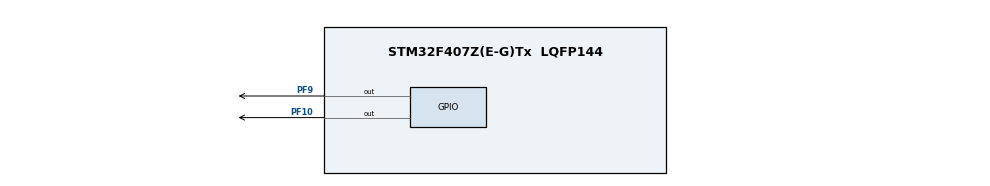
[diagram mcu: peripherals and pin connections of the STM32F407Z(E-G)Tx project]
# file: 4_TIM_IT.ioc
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Mcu.Family=STM32F4
Mcu.Name=STM32F407Z(E-G)Tx
Mcu.Package=LQFP144
NVIC.PriorityGroup=NVIC_PRIORITYGROUP_4
NVIC.TIM3_IRQn=true\:0\:0\:false\:false\:true\:true\:true
PF10.Signal=GPIO_Output
PF9.Signal=GPIO_Output
PH0-OSC_IN.Mode=HSE-External-Clock-Source
PH0-OSC_IN.Signal=RCC_OSC_IN
PH1-OSC_OUT.Mode=HSE-External-Clock-Source
PH1-OSC_OUT.Signal=RCC_OSC_OUT
ProjectManager.HeapSize=0x200
ProjectManager.StackSize=0x400
ProjectManager.TargetToolchain=MDK-ARM V5.27
RCC.48MHZClocksFreq_Value=84000000
RCC.AHBFreq_Value=168000000
RCC.APB1CLKDivider=RCC_HCLK_DIV4
RCC.APB1Freq_Value=42000000
RCC.APB1TimFreq_Value=84000000
RCC.APB2CLKDivider=RCC_HCLK_DIV2
RCC.APB2Freq_Value=84000000
RCC.APB2TimFreq_Value=168000000
RCC.CortexFreq_Value=168000000
RCC.HCLKFreq_Value=168000000
RCC.HSE_VALUE=8000000
RCC.HSI_VALUE=16000000
RCC.LSE_VALUE=32768
RCC.PLLM=8
RCC.PLLN=168
RCC.SYSCLKFreq_VALUE=168000000
RCC.SYSCLKSource=RCC_SYSCLKSOURCE_PLLCLK
RCC.VCOOutputFreq_Value=336000000
TIM3.AutoReloadPreload=TIM_AUTORELOAD_PRELOAD_DISABLE
TIM3.Period=9999
TIM3.Prescaler=8399
VP_TIM3_VS_ClockSourceINT.Mode=Internal
board=custom

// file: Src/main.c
/* USER CODE BEGIN Header */
/**
  ******************************************************************************
  * @file           : main.c
  * @brief          : Main program body
  ******************************************************************************
  * @attention
  *
  * <h2><center>&copy; Copyright (c) 2019 STMicroelectronics.
  * All rights reserved.</center></h2>
  *
  * This software component is licensed by ST under BSD 3-Clause license,
  * the "License"; You may not use this file except in compliance with the
  * License. You may obtain a copy of the License at:
  *                        opensource.org/licenses/BSD-3-Clause
  *
  ******************************************************************************
  */
/* USER CODE END Header */

#include "main.h"
#include "tim.h"
#include "gpio.h"

void SystemClock_Config(void);

int main(void)
{

  /* MCU Configuration--------------------------------------------------------*/

  /* Reset of all peripherals, Initializes the Flash interface and the Systick. */

  LL_APB2_GRP1_EnableClock(LL_APB2_GRP1_PERIPH_SYSCFG);
  LL_APB1_GRP1_EnableClock(LL_APB1_GRP1_PERIPH_PWR);

  NVIC_SetPriorityGrouping(NVIC_PRIORITYGROUP_4);

  /* System interrupt init*/

  /* Configure the system clock */
  SystemClock_Config();

  /* Initialize all configured peripherals */
  MX_GPIO_Init();
  MX_TIM3_Init();
  /* USER CODE BEGIN 2 */
	LL_TIM_EnableCounter(TIM3);
	LL_TIM_EnableIT_UPDATE(TIM3);
  /* USER CODE END 2 */

  /* Infinite loop */
  while (1)
  {

    /* USER CODE BEGIN 3 */
		LL_mDelay(1000);
		LL_GPIO_TogglePin(GPIOF,LL_GPIO_PIN_10);

  }
  /* USER CODE END 3 */
}

void SystemClock_Config(void)
{
  LL_FLASH_SetLatency(LL_FLASH_LATENCY_5);

  if(LL_FLASH_GetLatency() != LL_FLASH_LATENCY_5)
  {
  Error_Handler();
  }
  LL_PWR_SetRegulVoltageScaling(LL_PWR_REGU_VOLTAGE_SCALE1);
  LL_RCC_HSI_SetCalibTrimming(16);
  LL_RCC_HSI_Enable();

   /* Wait till HSI is ready */
  while(LL_RCC_HSI_IsReady() != 1)
  {

  }
  LL_RCC_PLL_ConfigDomain_SYS(LL_RCC_PLLSOURCE_HSI, LL_RCC_PLLM_DIV_8, 168, LL_RCC_PLLP_DIV_2);
  LL_RCC_PLL_Enable();

   /* Wait till PLL is ready */
  while(LL_RCC_PLL_IsReady() != 1)
  {

  }
  LL_RCC_SetAHBPrescaler(LL_RCC_SYSCLK_DIV_1);
  LL_RCC_SetAPB1Prescaler(LL_RCC_APB1_DIV_4);
  LL_RCC_SetAPB2Prescaler(LL_RCC_APB2_DIV_2);
  LL_RCC_SetSysClkSource(LL_RCC_SYS_CLKSOURCE_PLL);

   /* Wait till System clock is ready */
  while(LL_RCC_GetSysClkSource() != LL_RCC_SYS_CLKSOURCE_STATUS_PLL)
  {

  }
  LL_Init1msTick(168000000);
  LL_SYSTICK_SetClkSource(LL_SYSTICK_CLKSOURCE_HCLK);
  LL_SetSystemCoreClock(168000000);
}

void Error_Handler(void)
{
}

/************************ (C) COPYRIGHT STMicroelectronics *****END OF FILE****/
